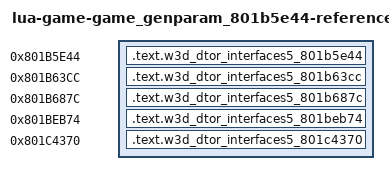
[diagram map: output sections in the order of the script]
/* Generated reference-only placements. All bodies are source-built. */
OUTPUT_FORMAT("elf32-powerpc")
OUTPUT_ARCH(powerpc)
ENTRY(w3d_dtor_interfaces5_801b5e44)
_SDA_BASE_ = 0x804b2540;
_SDA2_BASE_ = 0x804c2540;
fn_801b4c6c = 0x801b4c6c;
fn_801b5bd4 = 0x801b5bd4;
fn_801ea138 = 0x801ea138;
fn_801ea740 = 0x801ea740;
w3d_vtable_80414c18 = 0x80414c18;
w3d_vtable_80415028 = 0x80415028;
w3d_vtable_80415a50 = 0x80415a50;
w3d_vtable_80415a78 = 0x80415a78;
w3d_vtable_80415aa0 = 0x80415aa0;
SECTIONS {
  .text.w3d_dtor_interfaces5_801b5e44 0x801b5e44 : { *(.text.w3d_dtor_interfaces5_801b5e44) }
  .text.w3d_dtor_interfaces5_801b63cc 0x801b63cc : { *(.text.w3d_dtor_interfaces5_801b63cc) }
  .text.w3d_dtor_interfaces5_801b687c 0x801b687c : { *(.text.w3d_dtor_interfaces5_801b687c) }
  .text.w3d_dtor_interfaces5_801beb74 0x801beb74 : { *(.text.w3d_dtor_interfaces5_801beb74) }
  .text.w3d_dtor_interfaces5_801c4370 0x801c4370 : { *(.text.w3d_dtor_interfaces5_801c4370) }
  /DISCARD/ : { *(.text*) *(.rodata*) *(.data*) *(.bss*) *(.sdata*) *(.sbss*) *(.comment) }
}
